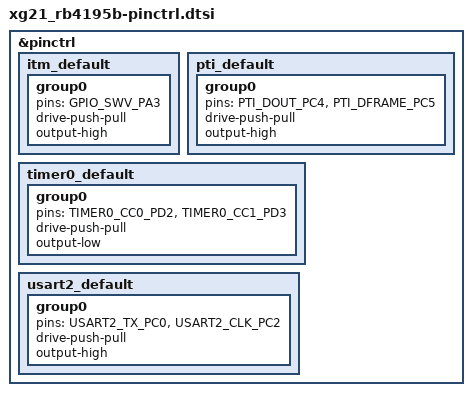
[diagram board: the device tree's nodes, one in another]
/*
 * Copyright (c) 2026 Silicon Laboratories Inc.
 *
 * SPDX-License-Identifier: Apache-2.0
 */

#include <zephyr/dt-bindings/pinctrl/silabs/xg21-pinctrl.h>

&pinctrl {
	itm_default: itm_default {
		group0 {
			pins = <GPIO_SWV_PA3>;
			drive-push-pull;
			output-high;
		};
	};

	pti_default: pti_default {
		group0 {
			pins = <PTI_DOUT_PC4>, <PTI_DFRAME_PC5>;
			drive-push-pull;
			output-high;
		};
	};

	timer0_default: timer0_default {
		group0 {
			pins = <TIMER0_CC0_PD2>, <TIMER0_CC1_PD3>;
			drive-push-pull;
			output-low;
		};
	};

	usart2_default: usart2_default {
		group0 {
			pins = <USART2_TX_PC0>, <USART2_CLK_PC2>;
			drive-push-pull;
			output-high;
		};
	};
};
